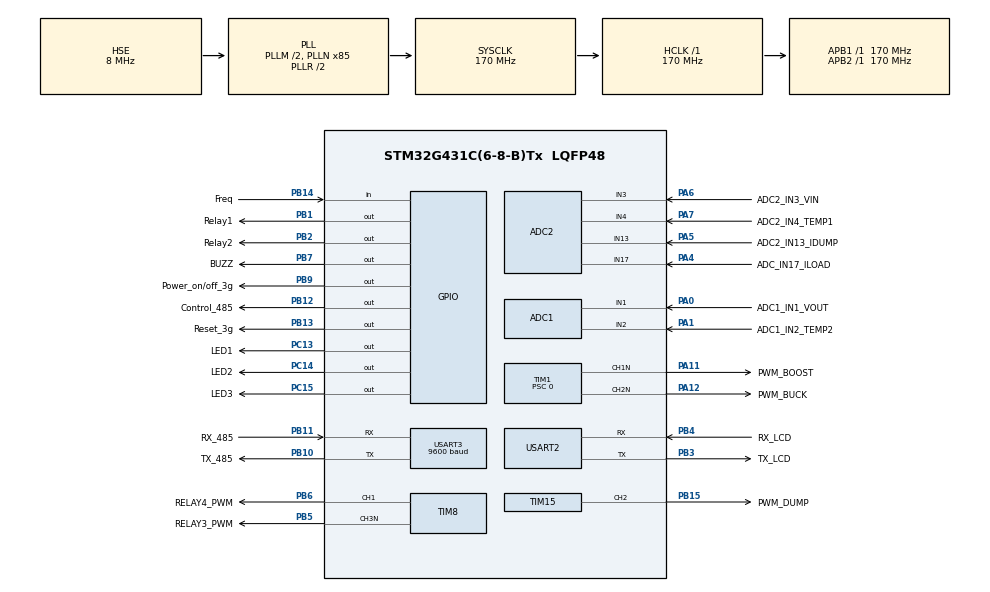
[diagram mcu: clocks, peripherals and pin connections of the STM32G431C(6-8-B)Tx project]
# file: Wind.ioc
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ADC1.Channel-0\#ChannelRegularConversion=ADC_CHANNEL_1
ADC1.Channel-1\#ChannelRegularConversion=ADC_CHANNEL_2
ADC1.ContinuousConvMode=ENABLE
ADC1.DMAContinuousRequests=ENABLE
ADC1.ExternalTrigConv=ADC_EXTERNALTRIG_T1_TRGO
ADC1.NbrOfConversion=2
ADC1.NbrOfConversionFlag=1
ADC1.OffsetNumber-0\#ChannelRegularConversion=ADC_OFFSET_NONE
ADC1.OffsetNumber-1\#ChannelRegularConversion=ADC_OFFSET_NONE
ADC1.Overrun=ADC_OVR_DATA_OVERWRITTEN
ADC1.Rank-0\#ChannelRegularConversion=1
ADC1.Rank-1\#ChannelRegularConversion=2
ADC1.SamplingTime-0\#ChannelRegularConversion=ADC_SAMPLETIME_92CYCLES_5
ADC1.SamplingTime-1\#ChannelRegularConversion=ADC_SAMPLETIME_92CYCLES_5
ADC1.master=1
ADC2.Channel-0\#ChannelRegularConversion=ADC_CHANNEL_3
ADC2.Channel-1\#ChannelRegularConversion=ADC_CHANNEL_4
ADC2.Channel-5\#ChannelRegularConversion=ADC_CHANNEL_13
ADC2.Channel-6\#ChannelRegularConversion=ADC_CHANNEL_17
ADC2.ContinuousConvMode=ENABLE
ADC2.DMAContinuousRequests=ENABLE
ADC2.EOCSelection=ADC_EOC_SINGLE_CONV
ADC2.EnableInjectedConversion=DISABLE
ADC2.ExternalTrigConv=ADC_EXTERNALTRIG_T1_TRGO
ADC2.LowPowerAutoWait=DISABLE
ADC2.NbrOfConversion=4
ADC2.NbrOfConversionFlag=1
ADC2.OffsetNumber-0\#ChannelRegularConversion=ADC_OFFSET_NONE
ADC2.OffsetNumber-1\#ChannelRegularConversion=ADC_OFFSET_NONE
ADC2.OffsetNumber-5\#ChannelRegularConversion=ADC_OFFSET_NONE
ADC2.OffsetNumber-6\#ChannelRegularConversion=ADC_OFFSET_NONE
ADC2.Overrun=ADC_OVR_DATA_OVERWRITTEN
ADC2.Rank-0\#ChannelRegularConversion=1
ADC2.Rank-1\#ChannelRegularConversion=2
ADC2.Rank-5\#ChannelRegularConversion=3
ADC2.Rank-6\#ChannelRegularConversion=4
ADC2.SamplingTime-0\#ChannelRegularConversion=ADC_SAMPLETIME_92CYCLES_5
ADC2.SamplingTime-1\#ChannelRegularConversion=ADC_SAMPLETIME_92CYCLES_5
ADC2.SamplingTime-5\#ChannelRegularConversion=ADC_SAMPLETIME_92CYCLES_5
ADC2.SamplingTime-6\#ChannelRegularConversion=ADC_SAMPLETIME_92CYCLES_5
Dma.ADC1.0.Direction=DMA_PERIPH_TO_MEMORY
Dma.ADC1.0.EventEnable=DISABLE
Dma.ADC1.0.Instance=DMA1_Channel1
Dma.ADC1.0.MemDataAlignment=DMA_MDATAALIGN_HALFWORD
Dma.ADC1.0.MemInc=DMA_MINC_ENABLE
Dma.ADC1.0.Mode=DMA_CIRCULAR
Dma.ADC1.0.PeriphDataAlignment=DMA_PDATAALIGN_HALFWORD
Dma.ADC1.0.PeriphInc=DMA_PINC_DISABLE
Dma.ADC1.0.Polarity=HAL_DMAMUX_REQ_GEN_RISING
Dma.ADC1.0.Priority=DMA_PRIORITY_VERY_HIGH
Dma.ADC1.0.RequestNumber=1
Dma.ADC1.0.SignalID=NONE
Dma.ADC1.0.SyncEnable=DISABLE
Dma.ADC1.0.SyncPolarity=HAL_DMAMUX_SYNC_NO_EVENT
Dma.ADC1.0.SyncRequestNumber=1
Dma.ADC1.0.SyncSignalID=NONE
Dma.ADC2.1.Direction=DMA_PERIPH_TO_MEMORY
Dma.ADC2.1.EventEnable=DISABLE
Dma.ADC2.1.Instance=DMA1_Channel3
Dma.ADC2.1.MemDataAlignment=DMA_MDATAALIGN_HALFWORD
Dma.ADC2.1.MemInc=DMA_MINC_ENABLE
Dma.ADC2.1.Mode=DMA_CIRCULAR
Dma.ADC2.1.PeriphDataAlignment=DMA_PDATAALIGN_HALFWORD
Dma.ADC2.1.PeriphInc=DMA_PINC_DISABLE
Dma.ADC2.1.Polarity=HAL_DMAMUX_REQ_GEN_RISING
Dma.ADC2.1.Priority=DMA_PRIORITY_VERY_HIGH
Dma.ADC2.1.RequestNumber=1
Dma.ADC2.1.SignalID=NONE
Dma.ADC2.1.SyncEnable=DISABLE
Dma.ADC2.1.SyncPolarity=HAL_DMAMUX_SYNC_NO_EVENT
Dma.ADC2.1.SyncRequestNumber=1
Dma.ADC2.1.SyncSignalID=NONE
Dma.Request0=ADC1
Dma.Request1=ADC2
Mcu.Family=STM32G4
Mcu.Name=STM32G431C(6-8-B)Tx
Mcu.Package=LQFP48
NVIC.PriorityGroup=NVIC_PRIORITYGROUP_4
NVIC.TIM1_BRK_TIM15_IRQn=true\:0\:0\:false\:false\:true\:true\:true\:true
NVIC.TIM1_CC_IRQn=true\:0\:0\:false\:false\:true\:true\:true\:true
NVIC.TIM8_BRK_IRQn=true\:0\:0\:false\:false\:true\:true\:true\:true
NVIC.TIM8_CC_IRQn=true\:0\:0\:false\:false\:true\:true\:true\:true
NVIC.USART2_IRQn=true\:0\:0\:false\:false\:true\:true\:true\:true
NVIC.USART3_IRQn=true\:0\:0\:false\:false\:true\:true\:true\:true
PA0.GPIO_Label=ADC1_IN1_VOUT
PA0.Mode=IN1-Single-Ended
PA0.Signal=ADC1_IN1
PA1.GPIO_Label=ADC1_IN2_TEMP2
PA1.Mode=IN2-Single-Ended
PA1.Signal=ADC1_IN2
PA11.GPIO_Label=PWM_BOOST
PA11.GPIO_PuPd=GPIO_NOPULL
PA11.GPIO_Speed=GPIO_SPEED_FREQ_LOW
PA11.Mode=PWM Generation1 CH1N
PA11.Signal=TIM1_CH1N
PA12.GPIO_Label=PWM_BUCK
PA12.GPIO_PuPd=GPIO_NOPULL
PA12.GPIO_Speed=GPIO_SPEED_FREQ_LOW
PA12.Mode=PWM Generation2 CH2N
PA12.Signal=TIM1_CH2N
PA13.Mode=Serial_Wire
PA13.Signal=SYS_JTMS-SWDIO
PA14.Mode=Serial_Wire
PA14.Signal=SYS_JTCK-SWCLK
PA4.GPIO_Label=ADC_IN17_ILOAD
PA4.Mode=IN17-Single-Ended
PA4.Signal=ADC2_IN17
PA5.GPIO_Label=ADC2_IN13_IDUMP
PA5.Mode=IN13-Single-Ended
PA5.Signal=ADC2_IN13
PA6.GPIO_Label=ADC2_IN3_VIN
PA6.Mode=IN3-Single-Ended
PA6.Signal=ADC2_IN3
PA7.GPIO_Label=ADC2_IN4_TEMP1
PA7.Mode=IN4-Single-Ended
PA7.Signal=ADC2_IN4
PB1.GPIO_Label=Relay1
PB1.GPIO_Speed=GPIO_SPEED_FREQ_LOW
PB1.Signal=GPIO_Output
PB10.GPIO_Label=TX_485
PB10.Mode=Asynchronous
PB10.Signal=USART3_TX
PB11.GPIO_Label=RX_485
PB11.Mode=Asynchronous
PB11.Signal=USART3_RX
PB12.GPIO_Label=Control_485
PB12.GPIO_PuPd=GPIO_NOPULL
PB12.GPIO_Speed=GPIO_SPEED_FREQ_VERY_HIGH
PB12.PinState=GPIO_PIN_RESET
PB12.Signal=GPIO_Output
PB13.GPIO_Label=Reset_3g
PB13.Signal=GPIO_Output
PB14.GPIO_Label=Freq
PB14.GPIO_PuPd=GPIO_NOPULL
PB14.Signal=GPIO_Input
PB15.GPIO_Label=PWM_DUMP
PB15.GPIO_PuPd=GPIO_NOPULL
PB15.GPIO_Speed=GPIO_SPEED_FREQ_LOW
PB15.Signal=S_TIM15_CH2
PB2.GPIO_Label=Relay2
PB2.GPIO_Speed=GPIO_SPEED_FREQ_LOW
PB2.Signal=GPIO_Output
PB3.GPIO_Label=TX_LCD
PB3.Mode=Asynchronous
PB3.Signal=USART2_TX
PB4.GPIO_Label=RX_LCD
PB4.Mode=Asynchronous
PB4.Signal=USART2_RX
PB5.GPIO_Label=RELAY3_PWM
PB5.Mode=PWM Generation3 CH3N
PB5.Signal=TIM8_CH3N
PB6.GPIO_Label=RELAY4_PWM
PB6.Signal=S_TIM8_CH1
PB7.GPIO_Label=BUZZ
PB7.Signal=GPIO_Output
PB9.GPIO_Label=Power_on/off_3g
PB9.Signal=GPIO_Output
PC13.GPIO_Label=LED1
PC13.GPIO_PuPd=GPIO_PULLUP
PC13.PinState=GPIO_PIN_RESET
PC13.Signal=GPIO_Output
PC14-OSC32_IN.GPIO_Label=LED2
PC14-OSC32_IN.PinState=GPIO_PIN_RESET
PC14-OSC32_IN.Signal=GPIO_Output
PC15-OSC32_OUT.GPIO_Label=LED3
PC15-OSC32_OUT.PinState=GPIO_PIN_RESET
PC15-OSC32_OUT.Signal=GPIO_Output
PF0-OSC_IN.Mode=HSE-External-Oscillator
PF0-OSC_IN.Signal=RCC_OSC_IN
PF1-OSC_OUT.Mode=HSE-External-Oscillator
PF1-OSC_OUT.Signal=RCC_OSC_OUT
ProjectManager.HeapSize=0x200
ProjectManager.StackSize=0x400
ProjectManager.TargetToolchain=STM32CubeIDE
RCC.ADC12Freq_Value=170000000
RCC.AHBFreq_Value=170000000
RCC.APB1Freq_Value=170000000
RCC.APB1TimFreq_Value=170000000
RCC.APB2Freq_Value=170000000
RCC.APB2TimFreq_Value=170000000
RCC.CortexFreq_Value=170000000
RCC.EXTERNAL_CLOCK_VALUE=12288000
RCC.HCLKFreq_Value=170000000
RCC.HSE_VALUE=8000000
RCC.HSI48_VALUE=48000000
RCC.HSI_VALUE=16000000
RCC.LSE_VALUE=32768
RCC.PLLM=RCC_PLLM_DIV2
RCC.PLLN=85
RCC.PLLSourceVirtual=RCC_PLLSOURCE_HSE
RCC.SYSCLKFreq_VALUE=170000000
RCC.SYSCLKSource=RCC_SYSCLKSOURCE_PLLCLK
RCC.USBFreq_Value=170000000
RCC.VCOOutputFreq_Value=340000000
SH.S_TIM15_CH2.0=TIM15_CH2,PWM Generation2 CH2
SH.S_TIM8_CH1.0=TIM8_CH1,PWM Generation1 CH1
TIM1.AutoReloadPreload=TIM_AUTORELOAD_PRELOAD_ENABLE
TIM1.Channel-Output\ Compare4\ No\ Output=TIM_CHANNEL_4
TIM1.Channel-PWM\ Generation1\ CH1N=TIM_CHANNEL_1
TIM1.Channel-PWM\ Generation2\ CH2N=TIM_CHANNEL_2
TIM1.Channel-PWM\ Generation3\ No\ Output=TIM_CHANNEL_3
TIM1.CounterMode=TIM_COUNTERMODE_UP
TIM1.LockLevel=TIM_LOCKLEVEL_OFF
TIM1.OC4Preload=ENABLE
TIM1.OCFastMode_PWM-PWM\ Generation1\ CH1N=TIM_OCFAST_ENABLE
TIM1.OCFastMode_PWM-PWM\ Generation2\ CH2N=TIM_OCFAST_ENABLE
TIM1.OCFastMode_PWM-PWM\ Generation3\ No\ Output=TIM_OCFAST_ENABLE
TIM1.OCMode_4=TIM_OCMODE_TOGGLE
TIM1.OffStateIDLEMode=TIM_OSSI_DISABLE
TIM1.OffStateRunMode=TIM_OSSR_DISABLE
TIM1.PeriodNoDither=65535
TIM1.Prescaler=0
TIM1.TIM_MasterOutputTrigger=TIM_TRGO_OC4REF
TIM15.AutoReloadPreload=TIM_AUTORELOAD_PRELOAD_ENABLE
TIM15.Channel-PWM\ Generation2\ CH2=TIM_CHANNEL_2
TIM15.PeriodNoDither=65535
TIM15.TIM_MasterOutputTrigger=TIM_TRGO_OC1REF
TIM8.Channel-PWM\ Generation1\ CH1=TIM_CHANNEL_1
TIM8.Channel-PWM\ Generation3\ CH3N=TIM_CHANNEL_3
USART2.VirtualMode-Asynchronous=VM_ASYNC
USART3.BaudRate=9600
USART3.DMADisableonRxErrorParam=ADVFEATURE_DMA_DISABLEONRXERROR
USART3.FIFOMode=FIFOMODE_DISABLE
USART3.OverrunDisableParam=ADVFEATURE_OVERRUN_DISABLE
USART3.RXFIFOThreshold=RXFIFO_THRESHOLD_FULL
USART3.VirtualMode-Asynchronous=VM_ASYNC
VP_ADC1_Vref_Input.Mode=IN-Vrefint
VP_TIM15_VS_ClockSourceINT.Mode=Internal
VP_TIM1_VS_ClockSourceINT.Mode=Internal
VP_TIM1_VS_no_output3.Mode=PWM Generation3 No Output
VP_TIM1_VS_no_output4.Mode=Output Compare4 No Output
VP_TIM8_VS_ClockSourceINT.Mode=Internal
board=custom

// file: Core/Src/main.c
/* USER CODE BEGIN Header */
/**
 ******************************************************************************
 * @file           : main.c
 * @brief          : Main program body
 ******************************************************************************
 * @attention
 *
 * Copyright (c) 2023 STMicroelectronics.
 * All rights reserved.
 *
 * This software is licensed under terms that can be found in the LICENSE file
 * in the root directory of this software component.
 * If no LICENSE file comes with this software, it is provided AS-IS.
 *
 ******************************************************************************
 */
/* USER CODE END Header */
#include "main.h"

/* USER CODE BEGIN Includes */
#include "driver/control/pin_func.h"
#include "app_main.h"

#include "lib/EC200_mqtt_application.h"
/* USER CODE END Includes */

ADC_HandleTypeDef hadc1;
ADC_HandleTypeDef hadc2;
DMA_HandleTypeDef hdma_adc1;
DMA_HandleTypeDef hdma_adc2;

UART_HandleTypeDef huart2;
UART_HandleTypeDef huart3;

void SystemClock_Config(void);
static void MX_GPIO_Init(void);
static void MX_DMA_Init(void);
static void MX_ADC1_Init(void);
static void MX_ADC2_Init(void);
static void MX_USART2_UART_Init(void);
static void MX_TIM1_Init(void);
static void MX_USART3_UART_Init(void);
static void MX_TIM15_Init(void);
static void MX_TIM8_Init(void);

int main(void)
{

  /* MCU Configuration--------------------------------------------------------*/

  /* Reset of all peripherals, Initializes the Flash interface and the Systick. */
  HAL_Init();

  /* Configure the system clock */
  SystemClock_Config();

  /* Initialize all configured peripherals */
  MX_GPIO_Init();
  MX_DMA_Init();
  MX_ADC1_Init();
  MX_ADC2_Init();
  MX_USART2_UART_Init();
  MX_TIM1_Init();
  MX_USART3_UART_Init();
  MX_TIM15_Init();
  MX_TIM8_Init();
  /* USER CODE BEGIN 2 */
  AppMainInit();

  /* USER CODE END 2 */

  /* Infinite loop */
  while (1)
  {

    /* USER CODE BEGIN 3 */
    AppMainProcess();
    if (EC200_MQTT_ConnectToServer())
    {
      Send_Data_To_Broker();
      Wait_Data_From_Broker();
//      Get_DateTime_From_Server(500);
    }

  }
  /* USER CODE END 3 */
}

void SystemClock_Config(void)
{
  RCC_OscInitTypeDef RCC_OscInitStruct = {0};
  RCC_ClkInitTypeDef RCC_ClkInitStruct = {0};

  /** Configure the main internal regulator output voltage
  */
  HAL_PWREx_ControlVoltageScaling(PWR_REGULATOR_VOLTAGE_SCALE1_BOOST);

  /** Initializes the RCC Oscillators according to the specified parameters
  * in the RCC_OscInitTypeDef structure.
  */
  RCC_OscInitStruct.OscillatorType = RCC_OSCILLATORTYPE_HSE;
  RCC_OscInitStruct.HSEState = RCC_HSE_ON;
  RCC_OscInitStruct.PLL.PLLState = RCC_PLL_ON;
  RCC_OscInitStruct.PLL.PLLSource = RCC_PLLSOURCE_HSE;
  RCC_OscInitStruct.PLL.PLLM = RCC_PLLM_DIV2;
  RCC_OscInitStruct.PLL.PLLN = 85;
  RCC_OscInitStruct.PLL.PLLP = RCC_PLLP_DIV2;
  RCC_OscInitStruct.PLL.PLLQ = RCC_PLLQ_DIV2;
  RCC_OscInitStruct.PLL.PLLR = RCC_PLLR_DIV2;
  if (HAL_RCC_OscConfig(&RCC_OscInitStruct) != HAL_OK)
  {
    Error_Handler();
  }

  /** Initializes the CPU, AHB and APB buses clocks
  */
  RCC_ClkInitStruct.ClockType = RCC_CLOCKTYPE_HCLK|RCC_CLOCKTYPE_SYSCLK
                              |RCC_CLOCKTYPE_PCLK1|RCC_CLOCKTYPE_PCLK2;
  RCC_ClkInitStruct.SYSCLKSource = RCC_SYSCLKSOURCE_PLLCLK;
  RCC_ClkInitStruct.AHBCLKDivider = RCC_SYSCLK_DIV1;
  RCC_ClkInitStruct.APB1CLKDivider = RCC_HCLK_DIV1;
  RCC_ClkInitStruct.APB2CLKDivider = RCC_HCLK_DIV1;

  if (HAL_RCC_ClockConfig(&RCC_ClkInitStruct, FLASH_LATENCY_4) != HAL_OK)
  {
    Error_Handler();
  }
}

static void MX_ADC1_Init(void)
{

  ADC_MultiModeTypeDef multimode = {0};
  ADC_ChannelConfTypeDef sConfig = {0};

  /** Common config
  */
  hadc1.Instance = ADC1;
  hadc1.Init.ClockPrescaler = ADC_CLOCK_SYNC_PCLK_DIV4;
  hadc1.Init.Resolution = ADC_RESOLUTION_12B;
  hadc1.Init.DataAlign = ADC_DATAALIGN_RIGHT;
  hadc1.Init.GainCompensation = 0;
  hadc1.Init.ScanConvMode = ADC_SCAN_ENABLE;
  hadc1.Init.EOCSelection = ADC_EOC_SINGLE_CONV;
  hadc1.Init.LowPowerAutoWait = DISABLE;
  hadc1.Init.ContinuousConvMode = ENABLE;
  hadc1.Init.NbrOfConversion = 2;
  hadc1.Init.DiscontinuousConvMode = DISABLE;
  hadc1.Init.ExternalTrigConv = ADC_EXTERNALTRIG_T1_TRGO;
  hadc1.Init.ExternalTrigConvEdge = ADC_EXTERNALTRIGCONVEDGE_RISING;
  hadc1.Init.DMAContinuousRequests = ENABLE;
  hadc1.Init.Overrun = ADC_OVR_DATA_OVERWRITTEN;
  hadc1.Init.OversamplingMode = DISABLE;
  if (HAL_ADC_Init(&hadc1) != HAL_OK)
  {
    Error_Handler();
  }

  /** Configure the ADC multi-mode
  */
  multimode.Mode = ADC_MODE_INDEPENDENT;
  if (HAL_ADCEx_MultiModeConfigChannel(&hadc1, &multimode) != HAL_OK)
  {
    Error_Handler();
  }

  /** Configure Regular Channel
  */
  sConfig.Channel = ADC_CHANNEL_1;
  sConfig.Rank = ADC_REGULAR_RANK_1;
  sConfig.SamplingTime = ADC_SAMPLETIME_92CYCLES_5;
  sConfig.SingleDiff = ADC_SINGLE_ENDED;
  sConfig.OffsetNumber = ADC_OFFSET_NONE;
  sConfig.Offset = 0;
  if (HAL_ADC_ConfigChannel(&hadc1, &sConfig) != HAL_OK)
  {
    Error_Handler();
  }

  /** Configure Regular Channel
  */
  sConfig.Channel = ADC_CHANNEL_2;
  sConfig.Rank = ADC_REGULAR_RANK_2;
  if (HAL_ADC_ConfigChannel(&hadc1, &sConfig) != HAL_OK)
  {
    Error_Handler();
  }

}

static void MX_ADC2_Init(void)
{

  ADC_ChannelConfTypeDef sConfig = {0};

  /** Common config
  */
  hadc2.Instance = ADC2;
  hadc2.Init.ClockPrescaler = ADC_CLOCK_SYNC_PCLK_DIV4;
  hadc2.Init.Resolution = ADC_RESOLUTION_12B;
  hadc2.Init.DataAlign = ADC_DATAALIGN_RIGHT;
  hadc2.Init.GainCompensation = 0;
  hadc2.Init.ScanConvMode = ADC_SCAN_ENABLE;
  hadc2.Init.EOCSelection = ADC_EOC_SINGLE_CONV;
  hadc2.Init.LowPowerAutoWait = DISABLE;
  hadc2.Init.ContinuousConvMode = ENABLE;
  hadc2.Init.NbrOfConversion = 4;
  hadc2.Init.DiscontinuousConvMode = DISABLE;
  hadc2.Init.ExternalTrigConv = ADC_EXTERNALTRIG_T1_TRGO;
  hadc2.Init.ExternalTrigConvEdge = ADC_EXTERNALTRIGCONVEDGE_RISING;
  hadc2.Init.DMAContinuousRequests = ENABLE;
  hadc2.Init.Overrun = ADC_OVR_DATA_OVERWRITTEN;
  hadc2.Init.OversamplingMode = DISABLE;
  if (HAL_ADC_Init(&hadc2) != HAL_OK)
  {
    Error_Handler();
  }

  /** Configure Regular Channel
  */
  sConfig.Channel = ADC_CHANNEL_3;
  sConfig.Rank = ADC_REGULAR_RANK_1;
  sConfig.SamplingTime = ADC_SAMPLETIME_92CYCLES_5;
  sConfig.SingleDiff = ADC_SINGLE_ENDED;
  sConfig.OffsetNumber = ADC_OFFSET_NONE;
  sConfig.Offset = 0;
  if (HAL_ADC_ConfigChannel(&hadc2, &sConfig) != HAL_OK)
  {
    Error_Handler();
  }

  /** Configure Regular Channel
  */
  sConfig.Channel = ADC_CHANNEL_4;
  sConfig.Rank = ADC_REGULAR_RANK_2;
  if (HAL_ADC_ConfigChannel(&hadc2, &sConfig) != HAL_OK)
  {
    Error_Handler();
  }

  /** Configure Regular Channel
  */
  sConfig.Channel = ADC_CHANNEL_13;
  sConfig.Rank = ADC_REGULAR_RANK_3;
  if (HAL_ADC_ConfigChannel(&hadc2, &sConfig) != HAL_OK)
  {
    Error_Handler();
  }

  /** Configure Regular Channel
  */
  sConfig.Channel = ADC_CHANNEL_17;
  sConfig.Rank = ADC_REGULAR_RANK_4;
  if (HAL_ADC_ConfigChannel(&hadc2, &sConfig) != HAL_OK)
  {
    Error_Handler();
  }

}

static void MX_TIM1_Init(void)
{

  LL_TIM_InitTypeDef TIM_InitStruct = {0};
  LL_TIM_OC_InitTypeDef TIM_OC_InitStruct = {0};
  LL_TIM_BDTR_InitTypeDef TIM_BDTRInitStruct = {0};

  LL_GPIO_InitTypeDef GPIO_InitStruct = {0};

  /* Peripheral clock enable */
  LL_APB2_GRP1_EnableClock(LL_APB2_GRP1_PERIPH_TIM1);

  /* TIM1 interrupt Init */
  NVIC_SetPriority(TIM1_BRK_TIM15_IRQn, NVIC_EncodePriority(NVIC_GetPriorityGrouping(),0, 0));
  NVIC_EnableIRQ(TIM1_BRK_TIM15_IRQn);
  NVIC_SetPriority(TIM1_CC_IRQn, NVIC_EncodePriority(NVIC_GetPriorityGrouping(),0, 0));
  NVIC_EnableIRQ(TIM1_CC_IRQn);

  TIM_InitStruct.Prescaler = 0;
  TIM_InitStruct.CounterMode = LL_TIM_COUNTERMODE_UP;
  TIM_InitStruct.Autoreload = 65535;
  TIM_InitStruct.ClockDivision = LL_TIM_CLOCKDIVISION_DIV1;
  TIM_InitStruct.RepetitionCounter = 0;
  LL_TIM_Init(TIM1, &TIM_InitStruct);
  LL_TIM_EnableARRPreload(TIM1);
  LL_TIM_SetClockSource(TIM1, LL_TIM_CLOCKSOURCE_INTERNAL);
  LL_TIM_OC_EnablePreload(TIM1, LL_TIM_CHANNEL_CH1);
  TIM_OC_InitStruct.OCMode = LL_TIM_OCMODE_PWM1;
  TIM_OC_InitStruct.OCState = LL_TIM_OCSTATE_DISABLE;
  TIM_OC_InitStruct.OCNState = LL_TIM_OCSTATE_DISABLE;
  TIM_OC_InitStruct.CompareValue = 0;
  TIM_OC_InitStruct.OCPolarity = LL_TIM_OCPOLARITY_HIGH;
  TIM_OC_InitStruct.OCNPolarity = LL_TIM_OCPOLARITY_HIGH;
  TIM_OC_InitStruct.OCIdleState = LL_TIM_OCIDLESTATE_LOW;
  TIM_OC_InitStruct.OCNIdleState = LL_TIM_OCIDLESTATE_LOW;
  LL_TIM_OC_Init(TIM1, LL_TIM_CHANNEL_CH1, &TIM_OC_InitStruct);
  LL_TIM_OC_EnableFast(TIM1, LL_TIM_CHANNEL_CH1);
  LL_TIM_OC_EnablePreload(TIM1, LL_TIM_CHANNEL_CH2);
  LL_TIM_OC_Init(TIM1, LL_TIM_CHANNEL_CH2, &TIM_OC_InitStruct);
  LL_TIM_OC_EnableFast(TIM1, LL_TIM_CHANNEL_CH2);
  LL_TIM_OC_EnablePreload(TIM1, LL_TIM_CHANNEL_CH3);
  LL_TIM_OC_Init(TIM1, LL_TIM_CHANNEL_CH3, &TIM_OC_InitStruct);
  LL_TIM_OC_EnableFast(TIM1, LL_TIM_CHANNEL_CH3);
  TIM_OC_InitStruct.OCMode = LL_TIM_OCMODE_TOGGLE;
  LL_TIM_OC_Init(TIM1, LL_TIM_CHANNEL_CH4, &TIM_OC_InitStruct);
  LL_TIM_OC_DisableFast(TIM1, LL_TIM_CHANNEL_CH4);
  LL_TIM_SetTriggerOutput(TIM1, LL_TIM_TRGO_OC4REF);
  LL_TIM_SetTriggerOutput2(TIM1, LL_TIM_TRGO2_RESET);
  LL_TIM_DisableMasterSlaveMode(TIM1);
  LL_TIM_OC_EnablePreload(TIM1, LL_TIM_CHANNEL_CH4);
  TIM_BDTRInitStruct.OSSRState = LL_TIM_OSSR_DISABLE;
  TIM_BDTRInitStruct.OSSIState = LL_TIM_OSSI_DISABLE;
  TIM_BDTRInitStruct.LockLevel = LL_TIM_LOCKLEVEL_OFF;
  TIM_BDTRInitStruct.DeadTime = 0;
  TIM_BDTRInitStruct.BreakState = LL_TIM_BREAK_DISABLE;
  TIM_BDTRInitStruct.BreakPolarity = LL_TIM_BREAK_POLARITY_HIGH;
  TIM_BDTRInitStruct.BreakFilter = LL_TIM_BREAK_FILTER_FDIV1;
  TIM_BDTRInitStruct.BreakAFMode = LL_TIM_BREAK_AFMODE_INPUT;
  TIM_BDTRInitStruct.Break2State = LL_TIM_BREAK2_DISABLE;
  TIM_BDTRInitStruct.Break2Polarity = LL_TIM_BREAK2_POLARITY_HIGH;
  TIM_BDTRInitStruct.Break2Filter = LL_TIM_BREAK2_FILTER_FDIV1;
  TIM_BDTRInitStruct.Break2AFMode = LL_TIM_BREAK_AFMODE_INPUT;
  TIM_BDTRInitStruct.AutomaticOutput = LL_TIM_AUTOMATICOUTPUT_DISABLE;
  LL_TIM_BDTR_Init(TIM1, &TIM_BDTRInitStruct);
  LL_AHB2_GRP1_EnableClock(LL_AHB2_GRP1_PERIPH_GPIOA);
  /**TIM1 GPIO Configuration
  PA11   ------> TIM1_CH1N
  PA12   ------> TIM1_CH2N
  */
  GPIO_InitStruct.Pin = LL_GPIO_PIN_11;
  GPIO_InitStruct.Mode = LL_GPIO_MODE_ALTERNATE;
  GPIO_InitStruct.Speed = LL_GPIO_SPEED_FREQ_LOW;
  GPIO_InitStruct.OutputType = LL_GPIO_OUTPUT_PUSHPULL;
  GPIO_InitStruct.Pull = LL_GPIO_PULL_NO;
  GPIO_InitStruct.Alternate = LL_GPIO_AF_6;
  LL_GPIO_Init(GPIOA, &GPIO_InitStruct);

  GPIO_InitStruct.Pin = LL_GPIO_PIN_12;
  GPIO_InitStruct.Mode = LL_GPIO_MODE_ALTERNATE;
  GPIO_InitStruct.Speed = LL_GPIO_SPEED_FREQ_LOW;
  GPIO_InitStruct.OutputType = LL_GPIO_OUTPUT_PUSHPULL;
  GPIO_InitStruct.Pull = LL_GPIO_PULL_NO;
  GPIO_InitStruct.Alternate = LL_GPIO_AF_6;
  LL_GPIO_Init(GPIOA, &GPIO_InitStruct);

}

static void MX_TIM8_Init(void)
{

  LL_TIM_InitTypeDef TIM_InitStruct = {0};
  LL_TIM_OC_InitTypeDef TIM_OC_InitStruct = {0};
  LL_TIM_BDTR_InitTypeDef TIM_BDTRInitStruct = {0};

  LL_GPIO_InitTypeDef GPIO_InitStruct = {0};

  /* Peripheral clock enable */
  LL_APB2_GRP1_EnableClock(LL_APB2_GRP1_PERIPH_TIM8);

  /* TIM8 interrupt Init */
  NVIC_SetPriority(TIM8_BRK_IRQn, NVIC_EncodePriority(NVIC_GetPriorityGrouping(),0, 0));
  NVIC_EnableIRQ(TIM8_BRK_IRQn);
  NVIC_SetPriority(TIM8_CC_IRQn, NVIC_EncodePriority(NVIC_GetPriorityGrouping(),0, 0));
  NVIC_EnableIRQ(TIM8_CC_IRQn);

  TIM_InitStruct.Prescaler = 0;
  TIM_InitStruct.CounterMode = LL_TIM_COUNTERMODE_UP;
  TIM_InitStruct.Autoreload = 65535;
  TIM_InitStruct.ClockDivision = LL_TIM_CLOCKDIVISION_DIV1;
  TIM_InitStruct.RepetitionCounter = 0;
  LL_TIM_Init(TIM8, &TIM_InitStruct);
  LL_TIM_DisableARRPreload(TIM8);
  LL_TIM_SetClockSource(TIM8, LL_TIM_CLOCKSOURCE_INTERNAL);
  LL_TIM_OC_EnablePreload(TIM8, LL_TIM_CHANNEL_CH1);
  TIM_OC_InitStruct.OCMode = LL_TIM_OCMODE_PWM1;
  TIM_OC_InitStruct.OCState = LL_TIM_OCSTATE_DISABLE;
  TIM_OC_InitStruct.OCNState = LL_TIM_OCSTATE_DISABLE;
  TIM_OC_InitStruct.CompareValue = 0;
  TIM_OC_InitStruct.OCPolarity = LL_TIM_OCPOLARITY_HIGH;
  TIM_OC_InitStruct.OCNPolarity = LL_TIM_OCPOLARITY_HIGH;
  TIM_OC_InitStruct.OCIdleState = LL_TIM_OCIDLESTATE_LOW;
  TIM_OC_InitStruct.OCNIdleState = LL_TIM_OCIDLESTATE_LOW;
  LL_TIM_OC_Init(TIM8, LL_TIM_CHANNEL_CH1, &TIM_OC_InitStruct);
  LL_TIM_OC_DisableFast(TIM8, LL_TIM_CHANNEL_CH1);
  LL_TIM_OC_EnablePreload(TIM8, LL_TIM_CHANNEL_CH3);
  LL_TIM_OC_Init(TIM8, LL_TIM_CHANNEL_CH3, &TIM_OC_InitStruct);
  LL_TIM_OC_DisableFast(TIM8, LL_TIM_CHANNEL_CH3);
  LL_TIM_SetTriggerOutput(TIM8, LL_TIM_TRGO_RESET);
  LL_TIM_SetTriggerOutput2(TIM8, LL_TIM_TRGO2_RESET);
  LL_TIM_DisableMasterSlaveMode(TIM8);
  TIM_BDTRInitStruct.OSSRState = LL_TIM_OSSR_DISABLE;
  TIM_BDTRInitStruct.OSSIState = LL_TIM_OSSI_DISABLE;
  TIM_BDTRInitStruct.LockLevel = LL_TIM_LOCKLEVEL_OFF;
  TIM_BDTRInitStruct.DeadTime = 0;
  TIM_BDTRInitStruct.BreakState = LL_TIM_BREAK_DISABLE;
  TIM_BDTRInitStruct.BreakPolarity = LL_TIM_BREAK_POLARITY_HIGH;
  TIM_BDTRInitStruct.BreakFilter = LL_TIM_BREAK_FILTER_FDIV1;
  TIM_BDTRInitStruct.BreakAFMode = LL_TIM_BREAK_AFMODE_INPUT;
  TIM_BDTRInitStruct.Break2State = LL_TIM_BREAK2_DISABLE;
  TIM_BDTRInitStruct.Break2Polarity = LL_TIM_BREAK2_POLARITY_HIGH;
  TIM_BDTRInitStruct.Break2Filter = LL_TIM_BREAK2_FILTER_FDIV1;
  TIM_BDTRInitStruct.Break2AFMode = LL_TIM_BREAK_AFMODE_INPUT;
  TIM_BDTRInitStruct.AutomaticOutput = LL_TIM_AUTOMATICOUTPUT_DISABLE;
  LL_TIM_BDTR_Init(TIM8, &TIM_BDTRInitStruct);
  LL_AHB2_GRP1_EnableClock(LL_AHB2_GRP1_PERIPH_GPIOB);
  /**TIM8 GPIO Configuration
  PB5   ------> TIM8_CH3N
  PB6   ------> TIM8_CH1
  */
  GPIO_InitStruct.Pin = LL_GPIO_PIN_5;
  GPIO_InitStruct.Mode = LL_GPIO_MODE_ALTERNATE;
  GPIO_InitStruct.Speed = LL_GPIO_SPEED_FREQ_LOW;
  GPIO_InitStruct.OutputType = LL_GPIO_OUTPUT_PUSHPULL;
  GPIO_InitStruct.Pull = LL_GPIO_PULL_NO;
  GPIO_InitStruct.Alternate = LL_GPIO_AF_3;
  LL_GPIO_Init(GPIOB, &GPIO_InitStruct);

  GPIO_InitStruct.Pin = LL_GPIO_PIN_6;
  GPIO_InitStruct.Mode = LL_GPIO_MODE_ALTERNATE;
  GPIO_InitStruct.Speed = LL_GPIO_SPEED_FREQ_LOW;
  GPIO_InitStruct.OutputType = LL_GPIO_OUTPUT_PUSHPULL;
  GPIO_InitStruct.Pull = LL_GPIO_PULL_NO;
  GPIO_InitStruct.Alternate = LL_GPIO_AF_5;
  LL_GPIO_Init(GPIOB, &GPIO_InitStruct);

}

static void MX_TIM15_Init(void)
{

  LL_TIM_InitTypeDef TIM_InitStruct = {0};
  LL_TIM_OC_InitTypeDef TIM_OC_InitStruct = {0};
  LL_TIM_BDTR_InitTypeDef TIM_BDTRInitStruct = {0};

  LL_GPIO_InitTypeDef GPIO_InitStruct = {0};

  /* Peripheral clock enable */
  LL_APB2_GRP1_EnableClock(LL_APB2_GRP1_PERIPH_TIM15);

  /* TIM15 interrupt Init */
  NVIC_SetPriority(TIM1_BRK_TIM15_IRQn, NVIC_EncodePriority(NVIC_GetPriorityGrouping(),0, 0));
  NVIC_EnableIRQ(TIM1_BRK_TIM15_IRQn);

  TIM_InitStruct.Prescaler = 0;
  TIM_InitStruct.CounterMode = LL_TIM_COUNTERMODE_UP;
  TIM_InitStruct.Autoreload = 65535;
  TIM_InitStruct.ClockDivision = LL_TIM_CLOCKDIVISION_DIV1;
  TIM_InitStruct.RepetitionCounter = 0;
  LL_TIM_Init(TIM15, &TIM_InitStruct);
  LL_TIM_EnableARRPreload(TIM15);
  LL_TIM_SetClockSource(TIM15, LL_TIM_CLOCKSOURCE_INTERNAL);
  LL_TIM_OC_EnablePreload(TIM15, LL_TIM_CHANNEL_CH2);
  TIM_OC_InitStruct.OCMode = LL_TIM_OCMODE_PWM1;
  TIM_OC_InitStruct.OCState = LL_TIM_OCSTATE_DISABLE;
  TIM_OC_InitStruct.OCNState = LL_TIM_OCSTATE_DISABLE;
  TIM_OC_InitStruct.CompareValue = 0;
  TIM_OC_InitStruct.OCPolarity = LL_TIM_OCPOLARITY_HIGH;
  TIM_OC_InitStruct.OCNPolarity = LL_TIM_OCPOLARITY_HIGH;
  TIM_OC_InitStruct.OCIdleState = LL_TIM_OCIDLESTATE_LOW;
  TIM_OC_InitStruct.OCNIdleState = LL_TIM_OCIDLESTATE_LOW;
  LL_TIM_OC_Init(TIM15, LL_TIM_CHANNEL_CH2, &TIM_OC_InitStruct);
  LL_TIM_OC_DisableFast(TIM15, LL_TIM_CHANNEL_CH2);
  LL_TIM_SetTriggerOutput(TIM15, LL_TIM_TRGO_OC1REF);
  LL_TIM_DisableMasterSlaveMode(TIM15);
  TIM_BDTRInitStruct.OSSRState = LL_TIM_OSSR_DISABLE;
  TIM_BDTRInitStruct.OSSIState = LL_TIM_OSSI_DISABLE;
  TIM_BDTRInitStruct.LockLevel = LL_TIM_LOCKLEVEL_OFF;
  TIM_BDTRInitStruct.DeadTime = 0;
  TIM_BDTRInitStruct.BreakState = LL_TIM_BREAK_DISABLE;
  TIM_BDTRInitStruct.BreakPolarity = LL_TIM_BREAK_POLARITY_HIGH;
  TIM_BDTRInitStruct.BreakFilter = LL_TIM_BREAK_FILTER_FDIV1;
  TIM_BDTRInitStruct.AutomaticOutput = LL_TIM_AUTOMATICOUTPUT_DISABLE;
  LL_TIM_BDTR_Init(TIM15, &TIM_BDTRInitStruct);
  LL_AHB2_GRP1_EnableClock(LL_AHB2_GRP1_PERIPH_GPIOB);
  /**TIM15 GPIO Configuration
  PB15   ------> TIM15_CH2
  */
  GPIO_InitStruct.Pin = LL_GPIO_PIN_15;
  GPIO_InitStruct.Mode = LL_GPIO_MODE_ALTERNATE;
  GPIO_InitStruct.Speed = LL_GPIO_SPEED_FREQ_LOW;
  GPIO_InitStruct.OutputType = LL_GPIO_OUTPUT_PUSHPULL;
  GPIO_InitStruct.Pull = LL_GPIO_PULL_NO;
  GPIO_InitStruct.Alternate = LL_GPIO_AF_1;
  LL_GPIO_Init(GPIOB, &GPIO_InitStruct);

}

static void MX_USART2_UART_Init(void)
{

  huart2.Instance = USART2;
  huart2.Init.BaudRate = 115200;
  huart2.Init.WordLength = UART_WORDLENGTH_8B;
  huart2.Init.StopBits = UART_STOPBITS_1;
  huart2.Init.Parity = UART_PARITY_NONE;
  huart2.Init.Mode = UART_MODE_TX_RX;
  huart2.Init.HwFlowCtl = UART_HWCONTROL_NONE;
  huart2.Init.OverSampling = UART_OVERSAMPLING_16;
  huart2.Init.OneBitSampling = UART_ONE_BIT_SAMPLE_DISABLE;
  huart2.Init.ClockPrescaler = UART_PRESCALER_DIV1;
  huart2.AdvancedInit.AdvFeatureInit = UART_ADVFEATURE_NO_INIT;
  if (HAL_UART_Init(&huart2) != HAL_OK)
  {
    Error_Handler();
  }
  if (HAL_UARTEx_SetTxFifoThreshold(&huart2, UART_TXFIFO_THRESHOLD_1_8) != HAL_OK)
  {
    Error_Handler();
  }
  if (HAL_UARTEx_SetRxFifoThreshold(&huart2, UART_RXFIFO_THRESHOLD_1_8) != HAL_OK)
  {
    Error_Handler();
  }
  if (HAL_UARTEx_DisableFifoMode(&huart2) != HAL_OK)
  {
    Error_Handler();
  }

}

static void MX_USART3_UART_Init(void)
{

  huart3.Instance = USART3;
  huart3.Init.BaudRate = 9600;
  huart3.Init.WordLength = UART_WORDLENGTH_8B;
  huart3.Init.StopBits = UART_STOPBITS_1;
  huart3.Init.Parity = UART_PARITY_NONE;
  huart3.Init.Mode = UART_MODE_TX_RX;
  huart3.Init.HwFlowCtl = UART_HWCONTROL_NONE;
  huart3.Init.OverSampling = UART_OVERSAMPLING_16;
  huart3.Init.OneBitSampling = UART_ONE_BIT_SAMPLE_DISABLE;
  huart3.Init.ClockPrescaler = UART_PRESCALER_DIV1;
  huart3.AdvancedInit.AdvFeatureInit = UART_ADVFEATURE_RXOVERRUNDISABLE_INIT|UART_ADVFEATURE_DMADISABLEONERROR_INIT;
  huart3.AdvancedInit.OverrunDisable = UART_ADVFEATURE_OVERRUN_DISABLE;
  huart3.AdvancedInit.DMADisableonRxError = UART_ADVFEATURE_DMA_DISABLEONRXERROR;
  if (HAL_UART_Init(&huart3) != HAL_OK)
  {
    Error_Handler();
  }
  if (HAL_UARTEx_SetTxFifoThreshold(&huart3, UART_TXFIFO_THRESHOLD_1_8) != HAL_OK)
  {
    Error_Handler();
  }
  if (HAL_UARTEx_SetRxFifoThreshold(&huart3, UART_RXFIFO_THRESHOLD_8_8) != HAL_OK)
  {
    Error_Handler();
  }
  if (HAL_UARTEx_DisableFifoMode(&huart3) != HAL_OK)
  {
    Error_Handler();
  }

}

static void MX_DMA_Init(void)
{

  /* DMA controller clock enable */
  __HAL_RCC_DMAMUX1_CLK_ENABLE();
  __HAL_RCC_DMA1_CLK_ENABLE();

}

static void MX_GPIO_Init(void)
{
  GPIO_InitTypeDef GPIO_InitStruct = {0};

  /* GPIO Ports Clock Enable */
  __HAL_RCC_GPIOC_CLK_ENABLE();
  __HAL_RCC_GPIOF_CLK_ENABLE();
  __HAL_RCC_GPIOA_CLK_ENABLE();
  __HAL_RCC_GPIOB_CLK_ENABLE();

  /*Configure GPIO pin Output Level */
  HAL_GPIO_WritePin(GPIOC, LED1_Pin|LED2_Pin|LED3_Pin, GPIO_PIN_RESET);

  /*Configure GPIO pin Output Level */
  HAL_GPIO_WritePin(GPIOB, Relay1_Pin|Relay2_Pin|Control_485_Pin|Reset_3g_Pin
                          |BUZZ_Pin|Power_on_off_3g_Pin, GPIO_PIN_RESET);

  /*Configure GPIO pin : LED1_Pin */
  GPIO_InitStruct.Pin = LED1_Pin;
  GPIO_InitStruct.Mode = GPIO_MODE_OUTPUT_PP;
  GPIO_InitStruct.Pull = GPIO_PULLUP;
  GPIO_InitStruct.Speed = GPIO_SPEED_FREQ_LOW;
  HAL_GPIO_Init(LED1_GPIO_Port, &GPIO_InitStruct);

  /*Configure GPIO pins : LED2_Pin LED3_Pin */
  GPIO_InitStruct.Pin = LED2_Pin|LED3_Pin;
  GPIO_InitStruct.Mode = GPIO_MODE_OUTPUT_PP;
  GPIO_InitStruct.Pull = GPIO_NOPULL;
  GPIO_InitStruct.Speed = GPIO_SPEED_FREQ_LOW;
  HAL_GPIO_Init(GPIOC, &GPIO_InitStruct);

  /*Configure GPIO pins : Relay1_Pin Relay2_Pin Reset_3g_Pin BUZZ_Pin
                           Power_on_off_3g_Pin */
  GPIO_InitStruct.Pin = Relay1_Pin|Relay2_Pin|Reset_3g_Pin|BUZZ_Pin
                          |Power_on_off_3g_Pin;
  GPIO_InitStruct.Mode = GPIO_MODE_OUTPUT_PP;
  GPIO_InitStruct.Pull = GPIO_NOPULL;
  GPIO_InitStruct.Speed = GPIO_SPEED_FREQ_LOW;
  HAL_GPIO_Init(GPIOB, &GPIO_InitStruct);

  /*Configure GPIO pin : Control_485_Pin */
  GPIO_InitStruct.Pin = Control_485_Pin;
  GPIO_InitStruct.Mode = GPIO_MODE_OUTPUT_PP;
  GPIO_InitStruct.Pull = GPIO_NOPULL;
  GPIO_InitStruct.Speed = GPIO_SPEED_FREQ_VERY_HIGH;
  HAL_GPIO_Init(Control_485_GPIO_Port, &GPIO_InitStruct);

  /*Configure GPIO pin : Freq_Pin */
  GPIO_InitStruct.Pin = Freq_Pin;
  GPIO_InitStruct.Mode = GPIO_MODE_INPUT;
  GPIO_InitStruct.Pull = GPIO_NOPULL;
  HAL_GPIO_Init(Freq_GPIO_Port, &GPIO_InitStruct);

}

void Error_Handler(void)
{
  __disable_irq();
  while (1)
  {
  }
}
